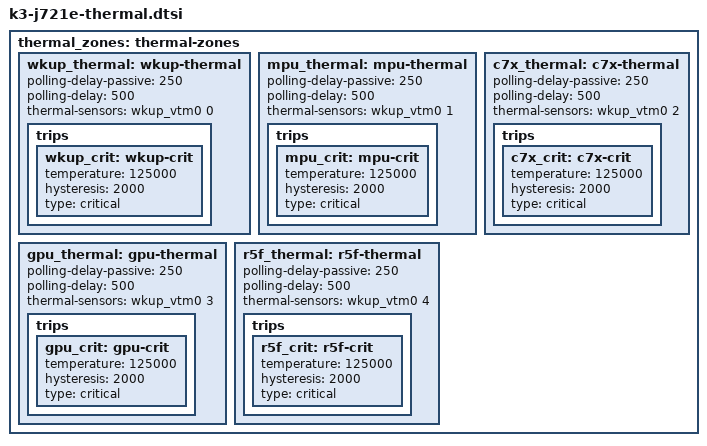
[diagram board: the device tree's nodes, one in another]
#include <dt-bindings/thermal/thermal.h>
thermal_zones: thermal-zones {
	wkup_thermal: wkup-thermal {
		polling-delay-passive = <250>;  
		polling-delay = <500>;  
		thermal-sensors = <&wkup_vtm0 0>;
		trips {
			wkup_crit: wkup-crit {
				temperature = <125000>;  
				hysteresis = <2000>;  
				type = "critical";
			};
		};
	};
	mpu_thermal: mpu-thermal {
		polling-delay-passive = <250>;  
		polling-delay = <500>;  
		thermal-sensors = <&wkup_vtm0 1>;
		trips {
			mpu_crit: mpu-crit {
				temperature = <125000>;  
				hysteresis = <2000>;  
				type = "critical";
			};
		};
	};
	c7x_thermal: c7x-thermal {
		polling-delay-passive = <250>;  
		polling-delay = <500>;  
		thermal-sensors = <&wkup_vtm0 2>;
		trips {
			c7x_crit: c7x-crit {
				temperature = <125000>;  
				hysteresis = <2000>;  
				type = "critical";
			};
		};
	};
	gpu_thermal: gpu-thermal {
		polling-delay-passive = <250>;  
		polling-delay = <500>;  
		thermal-sensors = <&wkup_vtm0 3>;
		trips {
			gpu_crit: gpu-crit {
				temperature = <125000>;  
				hysteresis = <2000>;  
				type = "critical";
			};
		};
	};
	r5f_thermal: r5f-thermal {
		polling-delay-passive = <250>;  
		polling-delay = <500>;  
		thermal-sensors = <&wkup_vtm0 4>;
		trips {
			r5f_crit: r5f-crit {
				temperature = <125000>;  
				hysteresis = <2000>;  
				type = "critical";
			};
		};
	};
};
